# STM32WBAxx register map
File version: 0.1
Registers are 32-bit, read-write, reset 0x0 unless marked. A register's access mark holds for its fields unless they carry their own. Offsets are from the block's base; [hi:lo] are bit positions; {n}, {i} and the like mark numbered series.

## RCC (part 2 of 3) — Reset and clock control
Base 0x46020C00
Same registers: SEC_RCC 0x56020C00
0x48 RCC_PLL3FRACR — RCC PLL3 fractional divider register
  [15:3] PLL3FRACN — Fractional part of the multiplication factor for PLL3 VCO Set and reset by software to control the fractional part of the multiplication factor of the VCO. These bits can be written at any time, allowing dynamic fine-tuning of the PLL3 VCO. VCO output frequency = Fref3_ck x (PLL3N + (PLL3FRACN / 213)), with: PLL3N must be between 4 and 512. PLL3FRACN can be between 0 and 213 - 1. The input frequency Fref3_ck must be between 4 and 16 MHz. In order to change the FRACN value on-the-fly even if the PLL is enabled, the application must proceed as follows: Set the bit PLL3FRACEN to 0. Write the new fractional value into PLL3FRACN. Set the bit PLL3FRACEN to 1.
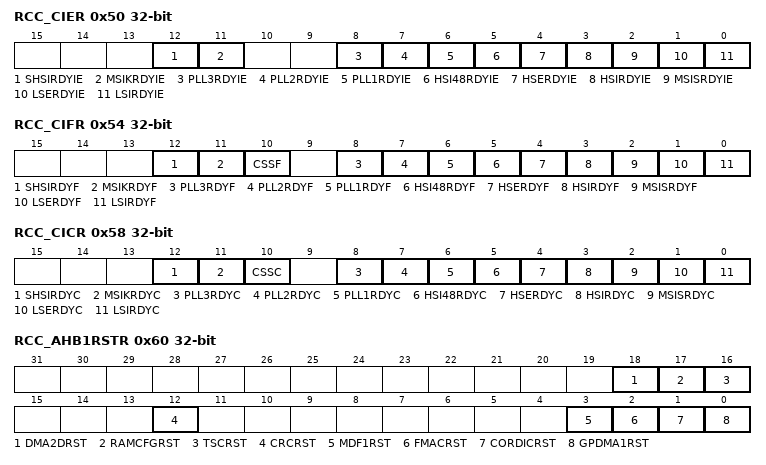
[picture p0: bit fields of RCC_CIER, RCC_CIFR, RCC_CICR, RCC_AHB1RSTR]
0x50 RCC_CIER — RCC clock interrupt enable register
  [12] SHSIRDYIE — SHSI ready interrupt enable Set and cleared by software to enable/disable interrupt caused by the SHSI oscillator stabilization.
    0=SHSI ready interrupt disabled; 1=SHSI ready interrupt enabled
  [11] MSIKRDYIE — MSIK ready interrupt enable Set and cleared by software to enable/disable interrupt caused by the MSIK oscillator stabilization.
    0=MSIK ready interrupt disabled; 1=MSIK ready interrupt enabled
  [8] PLL3RDYIE — PLL3 ready interrupt enable Set and cleared by software to enable/disable interrupt caused by PLL3 lock.
    0=PLL3 lock interrupt disabled; 1=PLL3 lock interrupt enabled
  [7] PLL2RDYIE — PLL2 ready interrupt enable Set and cleared by software to enable/disable interrupt caused by PLL2 lock.
    0=PLL2 lock interrupt disabled; 1=PLL2 lock interrupt enabled
  [6] PLL1RDYIE — PLL ready interrupt enable Set and cleared by software to enable/disable interrupt caused by PLL1 lock.
    0=PLL1 lock interrupt disabled; 1=PLL1 lock interrupt enabled
  [5] HSI48RDYIE — HSI48 ready interrupt enable Set and cleared by software to enable/disable interrupt caused by the HSI48 oscillator stabilization.
    0=HSI48 ready interrupt disabled; 1=HSI48 ready interrupt enabled
  [4] HSERDYIE — HSE ready interrupt enable Set and cleared by software to enable/disable interrupt caused by the HSE oscillator stabilization.
    0=HSE ready interrupt disabled; 1=HSE ready interrupt enabled
  [3] HSIRDYIE — HSI16 ready interrupt enable Set and cleared by software to enable/disable interrupt caused by the HSI16 oscillator stabilization.
    0=HSI16 ready interrupt disabled; 1=HSI16 ready interrupt enabled
  [2] MSISRDYIE — MSIS ready interrupt enable Set and cleared by software to enable/disable interrupt caused by the MSIS oscillator stabilization.
    0=MSIS ready interrupt disabled; 1=MSIS ready interrupt enabled
  [1] LSERDYIE — LSE ready interrupt enable Set and cleared by software to enable/disable interrupt caused by the LSE oscillator stabilization.
    0=LSE ready interrupt disabled; 1=LSE ready interrupt enabled
  [0] LSIRDYIE — LSI ready interrupt enable Set and cleared by software to enable/disable interrupt caused by the LSI oscillator stabilization.
    0=LSI ready interrupt disabled; 1=LSI ready interrupt enabled
0x54 RCC_CIFR ro — RCC clock interrupt flag register
  [12] SHSIRDYF — SHSI ready interrupt flag Set by hardware when the SHSI clock becomes stable and SHSIRDYIE is set. Cleared by software setting the SHSIRDYC bit.
    0=No clock ready interrupt caused by the SHSI oscillator; 1=Clock ready interrupt caused by the SHSI oscillator
  [11] MSIKRDYF — MSIK ready interrupt flag Set by hardware when the MSIK clock becomes stable and MSIKRDYIE is set. Cleared by software setting the MSIKRDYC bit.
    0=No clock ready interrupt caused by the MSIK oscillator; 1=Clock ready interrupt caused by the MSIK oscillator
  [10] CSSF — Clock security system interrupt flag Set by hardware when a failure is detected in the HSE oscillator. Cleared by software setting the CSSC bit.
    0=No clock security interrupt caused by HSE clock failure; 1=Clock security interrupt caused by HSE clock failure
  [8] PLL3RDYF — PLL3 ready interrupt flag Set by hardware when the PLL3 locks and PLL3RDYIE is set. Cleared by software setting the PLL3RDYC bit.
    0=No clock ready interrupt caused by PLL3 lock; 1=Clock ready interrupt caused by PLL3 lock
  [7] PLL2RDYF — PLL2 ready interrupt flag Set by hardware when the PLL2 locks and PLL2RDYIE is set. Cleared by software setting the PLL2RDYC bit.
    0=No clock ready interrupt caused by PLL2 lock; 1=Clock ready interrupt caused by PLL2 lock
  [6] PLL1RDYF — PLL1 ready interrupt flag Set by hardware when the PLL1 locks and PLL1RDYIE is set. Cleared by software setting the PLL1RDYC bit.
    0=No clock ready interrupt caused by PLL1 lock; 1=Clock ready interrupt caused by PLL1 lock
  [5] HSI48RDYF — HSI48 ready interrupt flag Set by hardware when the HSI48 clock becomes stable and HSI48RDYIE is set. Cleared by software setting the HSI48RDYC bit.
    0=No clock ready interrupt caused by the HSI48 oscillator; 1=Clock ready interrupt caused by the HSI48 oscillator
  [4] HSERDYF — HSE ready interrupt flag Set by hardware when the HSE clock becomes stable and HSERDYIE is set. Cleared by software setting the HSERDYC bit.
    0=No clock ready interrupt caused by the HSE oscillator; 1=Clock ready interrupt caused by the HSE oscillator
  [3] HSIRDYF — HSI16 ready interrupt flag Set by hardware when the HSI16 clock becomes stable and HSIRDYIE is set in a response to setting the HSION (see RCC_CR). When HSION is not set but the HSI16 oscillator is enabled by the peripheral through a clock request, this bit is not set and no interrupt is generated. Cleared by software setting the HSIRDYC bit.
    0=No clock ready interrupt caused by the HSI16 oscillator; 1=Clock ready interrupt caused by the HSI16 oscillator
  [2] MSISRDYF — MSIS ready interrupt flag Set by hardware when the MSIS clock becomes stable and MSISRDYIE is set. Cleared by software setting the MSISRDYC bit.
    0=No clock ready interrupt caused by the MSIS oscillator; 1=Clock ready interrupt caused by the MSIS oscillator
  [1] LSERDYF — LSE ready interrupt flag Set by hardware when the LSE clock becomes stable and LSERDYIE is set. Cleared by software setting the LSERDYC bit.
    0=No clock ready interrupt caused by the LSE oscillator; 1=Clock ready interrupt caused by the LSE oscillator
  [0] LSIRDYF — LSI ready interrupt flag Set by hardware when the LSI clock becomes stable and LSIRDYIE is set. Cleared by software setting the LSIRDYC bit.
    0=No clock ready interrupt caused by the LSI oscillator; 1=Clock ready interrupt caused by the LSI oscillator
0x58 RCC_CICR wo — RCC clock interrupt clear register
  [12] SHSIRDYC — SHSI oscillator ready interrupt clear Writing this bit to 1 clears the SHSIRDYF flag. Writing 0 has no effect.
  [11] MSIKRDYC — MSIK oscillator ready interrupt clear Writing this bit to 1 clears the MSIKRDYF flag. Writing 0 has no effect.
  [10] CSSC — Clock security system interrupt clear Writing this bit to 1 clears the CSSF flag. Writing 0 has no effect.
  [8] PLL3RDYC — PLL3 ready interrupt clear Writing this bit to 1 clears the PLL3RDYF flag. Writing 0 has no effect.
  [7] PLL2RDYC — PLL2 ready interrupt clear Writing this bit to 1 clears the PLL2RDYF flag. Writing 0 has no effect.
  [6] PLL1RDYC — PLL1 ready interrupt clear Writing this bit to 1 clears the PLL1RDYF flag. Writing 0 has no effect.
  [5] HSI48RDYC — HSI48 ready interrupt clear Writing this bit to 1 clears the HSI48RDYF flag. Writing 0 has no effect.
  [4] HSERDYC — HSE ready interrupt clear Writing this bit to 1 clears the HSERDYF flag. Writing 0 has no effect.
  [3] HSIRDYC — HSI16 ready interrupt clear Writing this bit to 1 clears the HSIRDYF flag. Writing 0 has no effect.
  [2] MSISRDYC — MSIS ready interrupt clear Writing this bit to 1 clears the MSISRDYF flag. Writing 0 has no effect.
  [1] LSERDYC — LSE ready interrupt clear Writing this bit to 1 clears the LSERDYF flag. Writing 0 has no effect.
  [0] LSIRDYC — LSI ready interrupt clear Writing this bit to 1 clears the LSIRDYF flag. Writing 0 has no effect.
0x60 RCC_AHB1RSTR — RCC AHB1 peripheral reset register
  [18] DMA2DRST — DMA2D reset Set and cleared by software.
    0=No effect; 1=Reset DMA2D
  [17] RAMCFGRST — RAMCFG reset Set and cleared by software.
    0=No effect; 1=Reset RAMCFG
  [16] TSCRST — TSC reset Set and cleared by software.
    0=No effect; 1=Reset TSC
  [12] CRCRST — CRC reset Set and cleared by software.
    0=No effect; 1=Reset CRC
  [3] MDF1RST — MDF1 reset Set and cleared by software.
    0=No effect; 1=Reset MDF1
  [2] FMACRST — FMAC reset Set and cleared by software.
    0=No effect; 1=Reset FMAC
  [1] CORDICRST — CORDIC reset Set and cleared by software.
    0=No effect; 1=Reset CORDIC
  [0] GPDMA1RST — GPDMA1 reset Set and cleared by software.
    0=No effect; 1=Reset GPDMA1
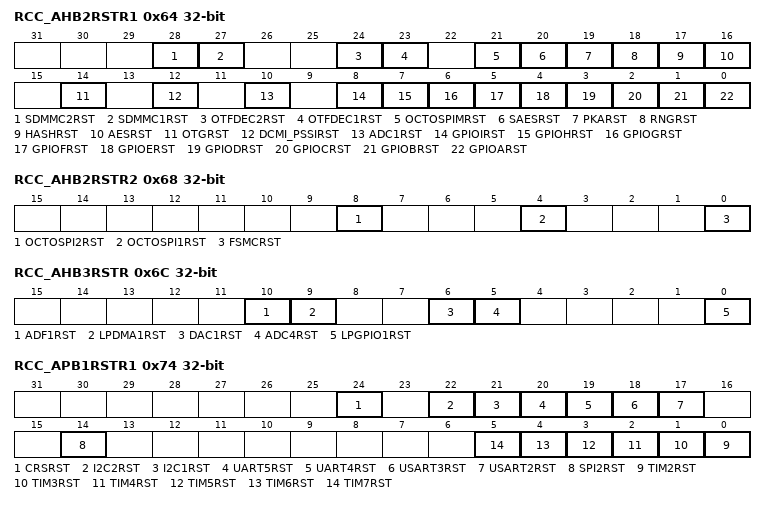
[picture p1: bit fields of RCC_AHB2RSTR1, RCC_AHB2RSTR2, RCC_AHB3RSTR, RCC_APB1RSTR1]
0x64 RCC_AHB2RSTR1 — RCC AHB2 peripheral reset register 1
  [28] SDMMC2RST — SDMMC2 reset Set and cleared by software.
    0=No effect; 1=Reset SDMMC2
  [27] SDMMC1RST — SDMMC1 reset Set and cleared by software.
    0=No effect; 1=Reset SDMMC1
  [24] OTFDEC2RST — OTFDEC2 reset Set and cleared by software.
    0=No effect; 1=Reset OTFDEC2
  [23] OTFDEC1RST — OTFDEC1 reset Set and cleared by software.
    0=No effect; 1=Reset OTFDEC1
  [21] OCTOSPIMRST — OCTOSPIM reset Set and cleared by software.
    0=No effect; 1=Reset OCTOSPIM
  [20] SAESRST — SAES hardware accelerator reset Set and cleared by software.
    0=No effect; 1=Reset SAES
  [19] PKARST — PKA reset Set and cleared by software.
    0=No effect; 1=Reset PKA
  [18] RNGRST — Random number generator reset Set and cleared by software.
    0=No effect; 1=Reset RNG
  [17] HASHRST — Hash reset Set and cleared by software.
    0=No effect; 1=Reset HASH
  [16] AESRST — AES hardware accelerator reset Set and cleared by software.
    0=No effect; 1=Reset AES
  [14] OTGRST — OTG_FS reset Set and cleared by software.
    0=No effect; 1=Reset OTG_FS
  [12] DCMI_PSSIRST — DCMI and PSSI reset Set and cleared by software.
    0=No effect; 1=Reset DCMI and PSSI
  [10] ADC1RST — ADC1 reset Set and cleared by software.
    0=No effect; 1=Reset ADC1
  [8] GPIOIRST — IO port I reset Set and cleared by software.
    0=No effect; 1=Reset IO port I
  [7] GPIOHRST — IO port H reset Set and cleared by software.
    0=No effect; 1=Reset IO port H
  [6] GPIOGRST — IO port G reset Set and cleared by software.
    0=No effect; 1=Reset IO port G
  [5] GPIOFRST — IO port F reset Set and cleared by software.
    0=No effect; 1=Reset IO port F
  [4] GPIOERST — IO port E reset Set and cleared by software.
    0=No effect; 1=Reset IO port E
  [3] GPIODRST — IO port D reset Set and cleared by software.
    0=No effect; 1=Reset IO port D
  [2] GPIOCRST — IO port C reset Set and cleared by software.
    0=No effect; 1=Reset IO port C
  [1] GPIOBRST — IO port B reset Set and cleared by software.
    0=No effect; 1=Reset IO port B
  [0] GPIOARST — IO port A reset Set and cleared by software.
    0=No effect; 1=Reset IO port A
0x68 RCC_AHB2RSTR2 — RCC AHB2 peripheral reset register 2
  [8] OCTOSPI2RST — OCTOSPI2 reset Set and cleared by software.
    0=No effect; 1=Reset OCTOSPI2
  [4] OCTOSPI1RST — OCTOSPI1 reset Set and cleared by software.
    0=No effect; 1=Reset OCTOSPI1
  [0] FSMCRST — Flexible memory controller reset Set and cleared by software.
    0=No effect; 1=Reset FSMC
0x6C RCC_AHB3RSTR — RCC AHB3 peripheral reset register
  [10] ADF1RST — ADF1 reset Set and cleared by software.
    0=No effect; 1=Reset ADF1
  [9] LPDMA1RST — LPDMA1 reset Set and cleared by software.
    0=No effect; 1=Reset LPDMA1
  [6] DAC1RST — DAC1 reset Set and cleared by software.
    0=No effect; 1=Reset DAC1
  [5] ADC4RST — ADC4 reset Set and cleared by software.
    0=No effect; 1=Reset ADC4 interface
  [0] LPGPIO1RST — LPGPIO1 reset Set and cleared by software.
    0=No effect; 1=Reset LPGPIO1
0x74 RCC_APB1RSTR1 — RCC APB1 peripheral reset register 1
  [24] CRSRST — CRS reset Set and cleared by software.
    0=No effect; 1=Reset the CRS
  [22] I2C2RST — I2C2 reset Set and cleared by software.
    0=No effect; 1=Reset I2C2
  [21] I2C1RST — I2C1 reset Set and cleared by software.
    0=No effect; 1=Reset I2C1
  [20] UART5RST — UART5 reset Set and cleared by software.
    0=No effect; 1=Reset UART5
  [19] UART4RST — UART4 reset Set and cleared by software.
    0=No effect; 1=Reset UART4
  [18] USART3RST — USART3 reset Set and cleared by software.
    0=No effect; 1=Reset USART3
  [17] USART2RST — USART2 reset Set and cleared by software.
    0=No effect; 1=Reset USART2
  [14] SPI2RST — SPI2 reset Set and cleared by software.
    0=No effect; 1=Reset SPI2
  [n-2] TIM{n}RST (n=2..7) — TIM{n} reset Set and cleared by software.
    0=No effect; 1=Reset TIM{n}
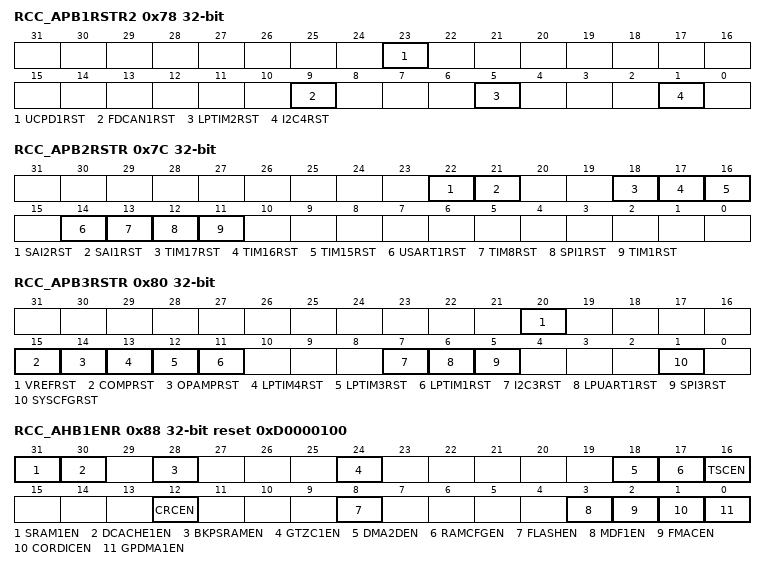
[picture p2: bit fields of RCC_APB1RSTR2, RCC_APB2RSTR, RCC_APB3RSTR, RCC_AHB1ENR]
0x78 RCC_APB1RSTR2 — RCC APB1 peripheral reset register 2
  [23] UCPD1RST — UCPD1 reset Set and cleared by software.
    0=No effect; 1=Reset UCPD1
  [9] FDCAN1RST — FDCAN1 reset Set and cleared by software.
    0=No effect; 1=Reset FDCAN1
  [5] LPTIM2RST — LPTIM2 reset Set and cleared by software.
    0=No effect; 1=Reset LPTIM2
  [1] I2C4RST — I2C4 reset Set and cleared by software
    0=No effect; 1=Reset I2C4
0x7C RCC_APB2RSTR — RCC APB2 peripheral reset register
  [22] SAI2RST — SAI2 reset Set and cleared by software.
    0=No effect; 1=Reset SAI2
  [21] SAI1RST — SAI1 reset Set and cleared by software.
    0=No effect; 1=Reset SAI1
  [18] TIM17RST — TIM17 reset Set and cleared by software.
    0=No effect; 1=Reset TIM17
  [17] TIM16RST — TIM16 reset Set and cleared by software.
    0=No effect; 1=Reset TIM16
  [16] TIM15RST — TIM15 reset Set and cleared by software.
    0=No effect; 1=Reset TIM15
  [14] USART1RST — USART1 reset Set and cleared by software.
    0=No effect; 1=Reset USART1
  [13] TIM8RST — TIM8 reset Set and cleared by software.
    0=No effect; 1=Reset TIM8
  [12] SPI1RST — SPI1 reset Set and cleared by software.
    0=No effect; 1=Reset SPI1
  [11] TIM1RST — TIM1 reset Set and cleared by software.
    0=No effect; 1=Reset TIM1
0x80 RCC_APB3RSTR — RCC APB3 peripheral reset register
  [20] VREFRST — VREFBUF reset Set and cleared by software.
    0=No effect; 1=Reset VREFBUF
  [15] COMPRST — COMP reset Set and cleared by software.
    0=No effect; 1=Reset COMP
  [14] OPAMPRST — OPAMP reset Set and cleared by software.
    0=No effect; 1=Reset OPAMP
  [13] LPTIM4RST — LPTIM4 reset Set and cleared by software.
    0=No effect; 1=Reset LPTIM4
  [12] LPTIM3RST — LPTIM3 reset Set and cleared by software.
    0=No effect; 1=Reset LPTIM3
  [11] LPTIM1RST — LPTIM1 reset Set and cleared by software.
    0=No effect; 1=Reset LPTIM1
  [7] I2C3RST — I2C3 reset Set and cleared by software.
    0=No effect; 1=Reset I2C3
  [6] LPUART1RST — LPUART1 reset Set and cleared by software.
    0=No effect; 1=Reset LPUART1
  [5] SPI3RST — SPI3 reset Set and cleared by software.
    0=No effect; 1=Reset SPI3
  [1] SYSCFGRST — SYSCFG reset Set and cleared by software.
    0=No effect; 1=Reset SYSCFG
0x88 RCC_AHB1ENR reset 0xD0000100 — RCC AHB1 peripheral clock enable register
  [31] SRAM1EN — SRAM1 clock enable Set and reset by software.
    0=SRAM1 clock disabled; 1=SRAM1 clock enabled
  [30] DCACHE1EN — DCACHE1 clock enable Set and reset by software. Note: DCACHE1 clock must be enabled when external memories are accessed through OCTOSPI1, OCTOSPI2 or FSMC, even if the DCACHE1 is bypassed.
    0=DCACHE1 clock disabled; 1=DCACHE1 clock enabled
  [28] BKPSRAMEN — BKPSRAM clock enable Set and reset by software.
    0=BKPSRAM clock disabled; 1=BKPSRAM clock enabled
  [24] GTZC1EN — GTZC1 clock enable Set and reset by software.
    0=GTZC1 clock disabled; 1=GTZC1 clock enabled
  [18] DMA2DEN — DMA2D clock enable Set and cleared by software.
    0=DMA2D clock disabled; 1=DMA2D clock enabled
  [17] RAMCFGEN — RAMCFG clock enable Set and cleared by software.
    0=RAMCFG clock disabled; 1=RAMCFG clock enabled
  [16] TSCEN — Touch sensing controller clock enable Set and cleared by software.
    0=TSC clock disabled; 1=TSC clock enabled
  [12] CRCEN — CRC clock enable Set and cleared by software.
    0=CRC clock disabled; 1=CRC clock enabled
  [8] FLASHEN — FLASH clock enable Set and cleared by software. This bit can be disabled only when the Flash memory is in power down mode.
    0=FLASH clock disabled; 1=FLASH clock enabled
  [3] MDF1EN — MDF1 clock enable Set and reset by software.
    0=MDF1 clock disabled; 1=MDF1 clock enabled
  [2] FMACEN — FMAC clock enable Set and reset by software.
    0=FMAC clock disabled; 1=FMAC clock enabled
  [1] CORDICEN — CORDIC clock enable Set and cleared by software.
    0=CORDIC clock disabled; 1=CORDIC clock enabled
  [0] GPDMA1EN — GPDMA1 clock enable Set and cleared by software.
    0=GPDMA1 clock disabled; 1=GPDMA1 clock enabled
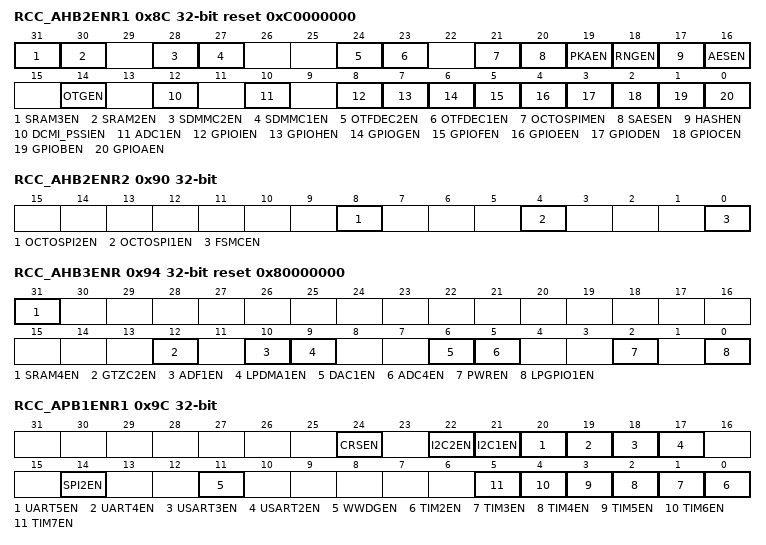
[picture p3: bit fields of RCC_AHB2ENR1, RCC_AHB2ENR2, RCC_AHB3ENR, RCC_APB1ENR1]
0x8C RCC_AHB2ENR1 reset 0xC0000000 — RCC AHB2 peripheral clock enable register 1
  [31] SRAM3EN — SRAM3 clock enable Set and reset by software.
    0=SRAM3 clock disabled; 1=SRAM3 clock enabled
  [30] SRAM2EN — SRAM2 clock enable Set and reset by software.
    0=SRAM2 clock disabled; 1=SRAM2 clock enabled
  [28] SDMMC2EN — SDMMC2 clock enable Set and cleared by software.
    0=SDMMC2 clock disabled; 1=SDMMC2 clock enabled
  [27] SDMMC1EN — SDMMC1 clock enable Set and cleared by software.
    0=SDMMC1 clock disabled; 1=SDMMC1 clock enabled
  [24] OTFDEC2EN — OTFDEC2 clock enable Set and cleared by software.
    0=OTFDEC2 clock disabled; 1=OTFDEC2 clock enabled
  [23] OTFDEC1EN — OTFDEC1 clock enable Set and cleared by software.
    0=OTFDEC1 clock disabled; 1=OTFDEC1 clock enabled
  [21] OCTOSPIMEN — OCTOSPIM clock enable Set and cleared by software.
    0=OCTOSPIM clock disabled; 1=OCTOSPIM clock enabled
  [20] SAESEN — SAES clock enable Set and cleared by software.
    0=SAES clock disabled; 1=SAES clock enabled
  [19] PKAEN — PKA clock enable Set and cleared by software.
    0=PKA clock disabled; 1=PKA clock enabled
  [18] RNGEN — RNG clock enable Set and cleared by software.
    0=RNG clock disabled; 1=RNG clock enabled
  [17] HASHEN — HASH clock enable Set and cleared by software
    0=HASH clock disabled; 1=HASH clock enabled
  [16] AESEN — AES clock enable Set and cleared by software.
    0=AES clock disabled; 1=AES clock enabled
  [14] OTGEN — OTG_FS clock enable Set and cleared by software.
    0=OTG_FS clock disabled; 1=OTG_FS clock enabled
  [12] DCMI_PSSIEN — DCMI and PSSI clock enable Set and cleared by software.
    0=DCMI and PSSI clock disabled; 1=DCMI and PSSI clock enabled
  [10] ADC1EN — ADC1 clock enable Set and cleared by software.
    0=ADC1 clock disabled; 1=ADC1 clock enabled
  [8] GPIOIEN — IO port I clock enable Set and cleared by software.
    0=IO port I clock disabled; 1=IO port I clock enabled
  [7] GPIOHEN — IO port H clock enable Set and cleared by software.
    0=IO port H clock disabled; 1=IO port H clock enabled
  [6] GPIOGEN — IO port G clock enable Set and cleared by software.
    0=IO port G clock disabled; 1=IO port G clock enabled
  [5] GPIOFEN — IO port F clock enable Set and cleared by software.
    0=IO port F clock disabled; 1=IO port F clock enabled
  [4] GPIOEEN — IO port E clock enable Set and cleared by software.
    0=IO port E clock disabled; 1=IO port E clock enabled
  [3] GPIODEN — IO port D clock enable Set and cleared by software.
    0=IO port D clock disabled; 1=IO port D clock enabled
  [2] GPIOCEN — IO port C clock enable Set and cleared by software.
    0=IO port C clock disabled; 1=IO port C clock enabled
  [1] GPIOBEN — IO port B clock enable Set and cleared by software.
    0=IO port B clock disabled; 1=IO port B clock enabled
  [0] GPIOAEN — IO port A clock enable Set and cleared by software.
    0=IO port A clock disabled; 1=IO port A clock enabled
0x90 RCC_AHB2ENR2 — RCC AHB2 peripheral clock enable register 2
  [8] OCTOSPI2EN — OCTOSPI2 clock enable Set and cleared by software.
    0=OCTOSPI2 clock disabled; 1=OCTOSPI2 clock enabled
  [4] OCTOSPI1EN — OCTOSPI1 clock enable Set and cleared by software.
    0=OCTOSPI1 clock disabled; 1=OCTOSPI1 clock enabled
  [0] FSMCEN — FSMC clock enable Set and cleared by software.
    0=FSMC clock disabled; 1=FSMC clock enabled
0x94 RCC_AHB3ENR reset 0x80000000 — RCC AHB3 peripheral clock enable register
  [31] SRAM4EN — SRAM4 clock enable Set and reset by software.
    0=SRAM4 clock disabled; 1=SRAM4 clock enabled
  [12] GTZC2EN — GTZC2 clock enable Set and cleared by software.
    0=GTZC2 clock disabled; 1=GTZC2 clock enabled
  [10] ADF1EN — ADF1 clock enable Set and cleared by software.
    0=ADF1 clock disabled; 1=ADF1 clock enabled
  [9] LPDMA1EN — LPDMA1 clock enable Set and cleared by software.
    0=LPDMA1 clock disabled; 1=LPDMA1 clock enabled
  [6] DAC1EN — DAC1 clock enable Set and cleared by software.
    0=DAC1 clock disabled; 1=DAC1 clock enabled
  [5] ADC4EN — ADC4 clock enable Set and cleared by software.
    0=ADC4 clock disabled; 1=ADC4 clock enabled
  [2] PWREN — PWR clock enable Set and cleared by software.
    0=PWR clock disabled; 1=PWR clock enabled
  [0] LPGPIO1EN — LPGPIO1 enable Set and cleared by software.
    0=LPGPIO1 clock disabled; 1=LPGPIO1 clock enabled
0x9C RCC_APB1ENR1 — RCC APB1 peripheral clock enable register 1
  [24] CRSEN — CRS clock enable Set and cleared by software.
    0=CRS clock disabled; 1=CRS clock enabled
  [22] I2C2EN — I2C2 clock enable Set and cleared by software.
    0=I2C2 clock disabled; 1=I2C2 clock enabled
  [21] I2C1EN — I2C1 clock enable Set and cleared by software.
    0=I2C1 clock disabled; 1=I2C1 clock enabled
  [20] UART5EN — UART5 clock enable Set and cleared by software.
    0=UART5 clock disabled; 1=UART5 clock enabled
  [19] UART4EN — UART4 clock enable Set and cleared by software.
    0=UART4 clock disabled; 1=UART4 clock enabled
  [18] USART3EN — USART3 clock enable Set and cleared by software.
    0=USART3 clock disabled; 1=USART3 clock enabled
  [17] USART2EN — USART2 clock enable Set and cleared by software.
    0=USART2 clock disabled; 1=USART2 clock enabled
  [14] SPI2EN — SPI2 clock enable Set and cleared by software.
    0=SPI2 clock disabled; 1=SPI2 clock enabled
  [11] WWDGEN — WWDG clock enable Set by software to enable the window watchdog clock. Reset by hardware system reset. This bit can also be set by hardware if the WWDG_SW option bit is reset.
    0=WWDG clock disabled; 1=WWDG clock enabled
  [n-2] TIM{n}EN (n=2..7) — TIM{n} clock enable Set and cleared by software.
    0=TIM{n} clock disabled; 1=TIM{n} clock enabled
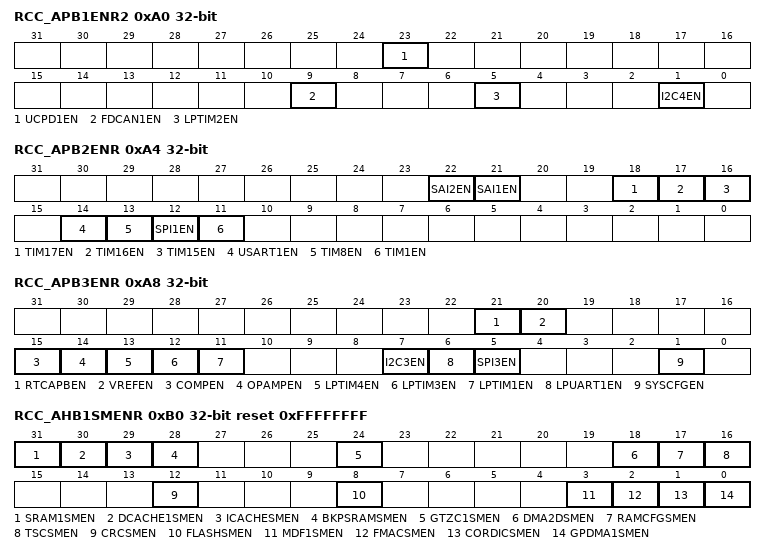
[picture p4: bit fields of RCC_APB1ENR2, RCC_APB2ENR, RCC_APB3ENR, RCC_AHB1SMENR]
0xA0 RCC_APB1ENR2 — RCC APB1 peripheral clock enable register 2
  [23] UCPD1EN — UCPD1 clock enable Set and cleared by software.
    0=UCPD1 clock disabled; 1=UCPD1 clock enabled
  [9] FDCAN1EN — FDCAN1 clock enable Set and cleared by software.
    0=FDCAN1 clock disabled; 1=FDCAN1 clock enabled
  [5] LPTIM2EN — LPTIM2 clock enable Set and cleared by software.
    0=LPTIM2 clock disabled; 1=LPTIM2 clock enabled
  [1] I2C4EN — I2C4 clock enable Set and cleared by software
    0=I2C4 clock disabled; 1=I2C4 clock enabled
0xA4 RCC_APB2ENR — RCC APB2 peripheral clock enable register
  [22] SAI2EN — SAI2 clock enable Set and cleared by software.
    0=SAI2 clock disabled; 1=SAI2 clock enabled
  [21] SAI1EN — SAI1 clock enable Set and cleared by software.
    0=SAI1 clock disabled; 1=SAI1 clock enabled
  [18] TIM17EN — TIM17 clock enable Set and cleared by software.
    0=TIM17 clock disabled; 1=TIM17 clock enabled
  [17] TIM16EN — TIM16 clock enable Set and cleared by software.
    0=TIM16 clock disabled; 1=TIM16 clock enabled
  [16] TIM15EN — TIM15 clock enable Set and cleared by software.
    0=TIM15 clock disabled; 1=TIM15 clock enabled
  [14] USART1EN — USART1clock enable Set and cleared by software.
    0=USART1 clock disabled; 1=USART1 clock enabled
  [13] TIM8EN — TIM8 clock enable Set and cleared by software.
    0=TIM8 clock disabled; 1=TIM8 clock enabled
  [12] SPI1EN — SPI1 clock enable Set and cleared by software.
    0=SPI1 clock disabled; 1=SPI1 clock enabled
  [11] TIM1EN — TIM1 clock enable Set and cleared by software.
    0=TIM1 clock disabled; 1=TIM1 clock enabled
0xA8 RCC_APB3ENR — RCC APB3 peripheral clock enable register
  [21] RTCAPBEN — RTC and TAMP APB clock enable Set and cleared by software.
    0=RTC and TAMP APB clock disabled; 1=RTC and TAMP APB clock enabled
  [20] VREFEN — VREFBUF clock enable Set and cleared by software.
    0=VREFBUF clock disabled; 1=VREFBUF clock enabled
  [15] COMPEN — COMP clock enable Set and cleared by software.
    0=COMP clock disabled; 1=COMP clock enabled
  [14] OPAMPEN — OPAMP clock enable Set and cleared by software.
    0=OPAMP clock disabled; 1=OPAMP clock enabled
  [13] LPTIM4EN — LPTIM4 clock enable Set and cleared by software.
    0=LPTIM4 clock disabled; 1=LPTIM4 clock enabled
  [12] LPTIM3EN — LPTIM3 clock enable Set and cleared by software.
    0=LPTIM3 clock disabled; 1=LPTIM3 clock enabled
  [11] LPTIM1EN — LPTIM1 clock enable Set and cleared by software.
    0=LPTIM1 clock disabled; 1=LPTIM1 clock enabled
  [7] I2C3EN — I2C3 clock enable Set and cleared by software.
    0=I2C3 clock disabled; 1=I2C3 clock enabled
  [6] LPUART1EN — LPUART1 clock enable Set and cleared by software.
    0=LPUART1 clock disabled; 1=LPUART1 clock enabled
  [5] SPI3EN — SPI3 clock enable Set and cleared by software.
    0=SPI3 clock disabled; 1=SPI3 clock enabled
  [1] SYSCFGEN — SYSCFG clock enable Set and cleared by software.
    0=SYSCFG clock disabled; 1=SYSCFG clock enabled
0xB0 RCC_AHB1SMENR reset 0xFFFFFFFF — RCC AHB1 peripheral clocks enable in Sleep and Stop modes register
  [31] SRAM1SMEN — SRAM1 clocks enable during Sleep and Stop modes Set and cleared by software.
    0=SRAM1 clocks disabled by the clock gating during Sleep and Stop modes; 1=SRAM1 clocks enabled by the clock gating during Sleep and Stop modes
  [30] DCACHE1SMEN — DCACHE1 clocks enable during Sleep and Stop modes Set and cleared by software.
    0=DCACHE1 clocks disabled by the clock gating during Sleep and Stop modes; 1=DCACHE1 clocks enabled by the clock gating during Sleep and Stop modes
  [29] ICACHESMEN — ICACHE clocks enable during Sleep and Stop modes Set and cleared by software.
    0=ICACHE clocks disabled by the clock gating during Sleep and Stop modes; 1=ICACHE clocks enabled by the clock gating during Sleep and Stop modes
  [28] BKPSRAMSMEN — BKPSRAM clocks enable during Sleep and Stop modes Set and cleared by software
    0=BKPSRAM clocks disabled by the clock gating during Sleep and Stop modes; 1=BKPSRAM clocks enabled by the clock gating during Sleep and Stop modes
  [24] GTZC1SMEN — GTZC1 clocks enable during Sleep and Stop modes Set and cleared by software.
    0=GTZC1 clocks disabled by the clock gating during Sleep and Stop modes; 1=GTZC1 clocks enabled by the clock gating during Sleep and Stop modes
  [18] DMA2DSMEN — DMA2D clocks enable during Sleep and Stop modes Set and cleared by software.
    0=DMA2D clocks disabled by the clock gating during Sleep and Stop modes; 1=DMA2D clocks enabled by the clock gating during Sleep and Stop modes
  [17] RAMCFGSMEN — RAMCFG clocks enable during Sleep and Stop modes Set and cleared by software.
    0=RAMCFG clocks disabled by the clock gating during Sleep and Stop modes; 1=RAMCFG clocks enabled by the clock gating during Sleep and Stop modes
  [16] TSCSMEN — TSC clocks enable during Sleep and Stop modes Set and cleared by software.
    0=TSC clocks disabled by the clock gating during Sleep and Stop modes; 1=TSC clocks enabled by the clock gating during Sleep and Stop modes
  [12] CRCSMEN — CRC clocks enable during Sleep and Stop modes Set and cleared by software.
    0=CRC clocks disabled by the clock gating during Sleep and Stop modes; 1=CRC clocks enabled by the clock gating during Sleep and Stop modes
  [8] FLASHSMEN — FLASH clocks enable during Sleep and Stop modes Set and cleared by software.
    0=FLASH clocks disabled by the clock gating during Sleep and Stop modes; 1=FLASH clocks enabled by the clock gating during Sleep and Stop modes
  [3] MDF1SMEN — MDF1 clocks enable during Sleep and Stop modes. Set and cleared by software. Note: This bit must be set to allow the peripheral to wake up from Stop modes.
    0=MDF1 clocks disabled by the clock gating during Sleep and Stop modes; 1=MDF1 clocks enabled by the clock gating during Sleep and Stop modes
  [2] FMACSMEN — FMAC clocks enable during Sleep and Stop modes. Set and cleared by software.
    0=FMAC clocks disabled by the clock gating during Sleep and Stop modes; 1=FMAC clocks enabled by the clock gating during Sleep and Stop modes
  [1] CORDICSMEN — CORDIC clocks enable during Sleep and Stop modes Set and cleared by software during Sleep mode.
    0=CORDIC clocks disabled by the clock gating during Sleep and Stop modes; 1=CORDIC clocks enabled by the clock gating during Sleep and Stop modes
  [0] GPDMA1SMEN — GPDMA1 clocks enable during Sleep and Stop modes Set and cleared by software. Note: This bit must be set to allow the peripheral to wake up from Stop modes.
    0=GPDMA1 clocks disabled by the clock gating during Sleep and Stop modes; 1=GPDMA1 clocks enabled by the clock gating during Sleep and Stop modes
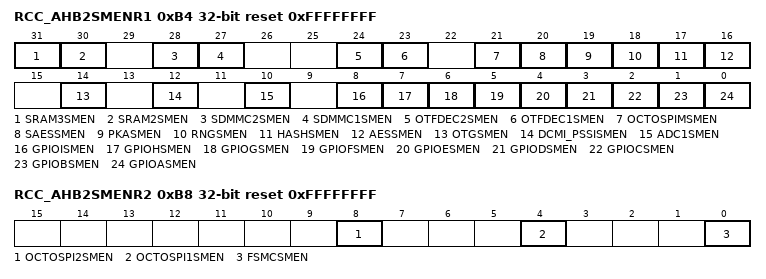
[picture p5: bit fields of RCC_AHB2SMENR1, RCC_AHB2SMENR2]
0xB4 RCC_AHB2SMENR1 reset 0xFFFFFFFF — RCC AHB2 peripheral clocks enable in Sleep and Stop modes register 1
  [31] SRAM3SMEN — SRAM3 clocks enable during Sleep and Stop modes Set and cleared by software.
    0=SRAM3 clocks disabled by the clock gating during Sleep and Stop modes; 1=SRAM3 clocks enabled by the clock gating during Sleep and Stop modes
  [30] SRAM2SMEN — SRAM2 clocks enable during Sleep and Stop modes Set and cleared by software.
    0=SRAM2 clocks disabled by the clock gating during Sleep and Stop modes; 1=SRAM2 clocks enabled by the clock gating during Sleep and Stop modes
  [28] SDMMC2SMEN — SDMMC2 clocks enable during Sleep and Stop modes Set and cleared by software.
    0=SDMMC2 clocks disabled by the clock gating during Sleep and Stop modes; 1=SDMMC2 clocks enabled by the clock gating during Sleep and Stop modes
  [27] SDMMC1SMEN — SDMMC1 clocks enable during Sleep and Stop modes Set and cleared by software.
    0=SDMMC1 clocks disabled by the clock gating during Sleep and Stop modes; 1=SDMMC1 clocks enabled by the clock gating during Sleep and Stop modes
  [24] OTFDEC2SMEN — OTFDEC2 clocks enable during Sleep and Stop modes Set and cleared by software.
    0=OTFDEC2 clocks disabled by the clock gating during Sleep and Stop modes; 1=OTFDEC2 clocks enabled by the clock gating during Sleep and Stop modes
  [23] OTFDEC1SMEN — OTFDEC1 clocks enable during Sleep and Stop modes Set and cleared by software.
    0=OTFDEC1 clocks disabled by the clock gating during Sleep and Stop modes; 1=OTFDEC1 clocks enabled by the clock gating during Sleep and Stop modes
  [21] OCTOSPIMSMEN — OCTOSPIM clocks enable during Sleep and Stop modes Set and cleared by software.
    0=OCTOSPIM clocks disabled by the clock gating during Sleep and Stop modes; 1=OCTOSPIM clocks enabled by the clock gating during Sleep and Stop modes
  [20] SAESSMEN — SAES accelerator clocks enable during Sleep and Stop modes Set and cleared by software.
    0=SAES clocks disabled by the clock gating during Sleep and Stop modes; 1=SAES clocks enabled by the clock gating during Sleep and Stop modes
  [19] PKASMEN — PKA clocks enable during Sleep and Stop modes Set and cleared by software.
    0=PKA clocks disabled by the clock gating during Sleep and Stop modes; 1=PKA clocks enabled by the clock gating during Sleep and Stop modes
  [18] RNGSMEN — Random number generator (RNG) clocks enable during Sleep and Stop modes Set and cleared by software.
    0=RNG clocks disabled by the clock gating during Sleep and Stop modes; 1=RNG clocks enabled by the clock gating during Sleep and Stop modes
  [17] HASHSMEN — HASH clock enable during Sleep and Stop modes Set and cleared by software
    0=HASH clocks disabled by the clock gating during Sleep and Stop modes; 1=HASH clocks enabled by the clock gating during Sleep and Stop modes
  [16] AESSMEN — AES clock enable during Sleep and Stop modes Set and cleared by software
    0=AES clocks disabled by the clock gating during Sleep and Stop modes; 1=AES clocks enabled by the clock gating during Sleep and Stop modes
  [14] OTGSMEN — OTG_FS clocks enable during Sleep and Stop modes Set and cleared by software.
    0=OTG_FS clocks disabled by the clock gating during Sleep and Stop modes; 1=OTG_FS clocks enabled by the clock gating during Sleep and Stop modes
  [12] DCMI_PSSISMEN — DCMI and PSSI clocks enable during Sleep and Stop modes Set and cleared by software.
    0=DCMI and PSSI clocks disabled by the clock gating during Sleep and Stop modes; 1=DCMI and PSSI clocks enabled by the clock gating during Sleep and Stop modes
  [10] ADC1SMEN — ADC1 clocks enable during Sleep and Stop modes Set and cleared by software.
    0=ADC1 clocks disabled by the clock gating during Sleep and Stop modes; 1=ADC1 clocks enabled by the clock gating during Sleep and Stop modes
  [8] GPIOISMEN — IO port I clocks enable during Sleep and Stop modes Set and cleared by software.
    0=IO port I clocks disabled by the clock gating during Sleep and Stop modes; 1=IO port I clocks enabled by the clock gating during Sleep and Stop modes
  [7] GPIOHSMEN — IO port H clocks enable during Sleep and Stop modes Set and cleared by software.
    0=IO port H clocks disabled by the clock gating during Sleep and Stop modes; 1=IO port H clocks enabled by the clock gating during Sleep and Stop modes
  [6] GPIOGSMEN — IO port G clocks enable during Sleep and Stop modes Set and cleared by software.
    0=IO port G clocks disabled by the clock gating during Sleep and Stop modes; 1=IO port G clocks enabled by the clock gating during Sleep and Stop modes
  [5] GPIOFSMEN — IO port F clocks enable during Sleep and Stop modes Set and cleared by software.
    0=IO port F clocks disabled by the clock gating during Sleep and Stop modes; 1=IO port F clocks enabled by the clock gating during Sleep and Stop modes
  [4] GPIOESMEN — IO port E clocks enable during Sleep and Stop modes Set and cleared by software.
    0=IO port E clocks disabled by the clock gating during Sleep and Stop modes; 1=IO port E clocks enabled by the clock gating during Sleep and Stop modes
  [3] GPIODSMEN — IO port D clocks enable during Sleep and Stop modes Set and cleared by software.
    0=IO port D clocks disabled by the clock gating during Sleep and Stop modes; 1=IO port D clocks enabled by the clock gating during Sleep and Stop modes
  [2] GPIOCSMEN — IO port C clocks enable during Sleep and Stop modes Set and cleared by software.
    0=IO port C clocks disabled by the clock gating during Sleep and Stop modes; 1=IO port C clocks enabled by the clock gating during Sleep and Stop modes
  [1] GPIOBSMEN — IO port B clocks enable during Sleep and Stop modes Set and cleared by software.
    0=IO port B clocks disabled by the clock gating during Sleep and Stop modes; 1=IO port B clocks enabled by the clock gating during Sleep and Stop modes
  [0] GPIOASMEN — IO port A clocks enable during Sleep and Stop modes Set and cleared by software.
    0=IO port A clocks disabled by the clock gating during Sleep and Stop modes; 1=IO port A clocks enabled by the clock gating during Sleep and Stop modes
0xB8 RCC_AHB2SMENR2 reset 0xFFFFFFFF — RCC AHB2 peripheral clocks enable in Sleep and Stop modes register 2
  [8] OCTOSPI2SMEN — OCTOSPI2 clocks enable during Sleep and Stop modes Set and cleared by software.
    0=OCTOSPI2 clocks disabled by the clock gating during Sleep and Stop modes; 1=OCTOSPI2 clocks enabled by the clock gating during Sleep and Stop modes
  [4] OCTOSPI1SMEN — OCTOSPI1 clocks enable during Sleep and Stop modes Set and cleared by software.
    0=OCTOSPI1 clocks disabled by the clock gating during Sleep and Stop modes; 1=OCTOSPI1 clocks enabled by the clock gating during Sleep and Stop modes
  [0] FSMCSMEN — FSMC clocks enable during Sleep and Stop modes Set and cleared by software.
    0=FSMC clocks disabled by the clock gating during Sleep and Stop modes; 1=FSMC clocks enabled by the clock gating during Sleep and Stop modes
